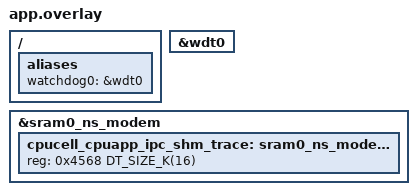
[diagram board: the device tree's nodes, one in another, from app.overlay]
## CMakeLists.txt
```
# SPDX-FileCopyrightText: 2026 ETH Zurich and University of Bologna
# SPDX-License-Identifier: Apache-2.0
#
# Authors:
# - Philip Wiese <wiesep@iis.ee.ethz.ch>

# SENSEI LPWAN shield firmware for the nRF9151 (NCS v3.4.1). It serves the nRF5340 over SPI.
# Board: sensei_lpwan_nrf9151/nrf9151/ns, from the SENSEI SDK.
#   export SENSEI_SDK_ROOT=<path to the SENSEI SDK>
#   cd $SENSEI_SDK_ROOT/NRF/apps/lpwan_shield
#   west build -b sensei_lpwan_nrf9151/nrf9151/ns -- -DEXTRA_ZEPHYR_MODULES=$SENSEI_SDK_ROOT/NRF \
#     -DEXTRA_CONF_FILE=conf/debug.conf

cmake_minimum_required(VERSION 3.20.0)

if(NOT DEFINED ENV{SENSEI_SDK_ROOT})
  message(FATAL_ERROR "Set SENSEI_SDK_ROOT to the SENSEI SDK.")
endif()

# The SDK provides the board, the devicetree bindings and the libraries sensei_link and sensei_lpwan.
list(APPEND EXTRA_ZEPHYR_MODULES $ENV{SENSEI_SDK_ROOT}/NRF)

find_package(Zephyr REQUIRED HINTS $ENV{ZEPHYR_BASE})
project(sensei_lpwan_shield)

target_sources(app PRIVATE
  src/main.c
  src/diag.c
  src/service.c
)
target_include_directories(app PRIVATE src)

if(CONFIG_LPWAN_SHIELD_SIM)
  # native_sim: the link is a socket, the modem and the LR1121 are fakes (sim/README.md). The headers of the modem
  # library, lte_lc and date_time are the real ones of NCS: the fakes must have their signatures.
  target_sources(app PRIVATE sim/sim_shield.c sim/sim_link.c)
  target_include_directories(app PRIVATE sim ${ZEPHYR_BASE}/boards/native/native_sim
    ${ZEPHYR_NRF_MODULE_DIR}/include ${ZEPHYR_NRFXLIB_MODULE_DIR}/nrf_modem/include)
  # what the Kconfig of the modem libraries would define on the board, and lte.c asks for
  target_compile_definitions(app PRIVATE
    CONFIG_LTE_LC_NETWORK_REGISTRATION_MODULE=1 CONFIG_LTE_LC_PSM_MODULE=1 CONFIG_LTE_LC_EDRX_MODULE=1
    CONFIG_LTE_LC_RAI_MODULE=1 CONFIG_LTE_LC_CONN_EVAL_MODULE=1 CONFIG_LTE_PROPRIETARY_PSM_REQ=1)
else()
  target_sources(app PRIVATE src/link.c)
endif()
# The trial rule and the image TLVs of the OTA helpers (pure headers, no Zephyr dependency): "ota/sensei_ota_trial.h",
# "ota/sensei_ota_image.h".
target_include_directories(app PRIVATE ${CMAKE_CURRENT_LIST_DIR}/../../system)

target_sources_ifdef(CONFIG_LPWAN_SHIELD_DFU app PRIVATE src/dfu.c)

if(CONFIG_LPWAN_SHIELD_DFU)
  # The kind of this board: sysbuild.cmake adds it to the signed image as a protected TLV (imgtool --custom-tlv 0xa0),
  # and the app takes the string from the same imgtool arguments, so the two cannot differ.
  if(CONFIG_MCUBOOT_EXTRA_IMGTOOL_ARGS MATCHES "--custom-tlv 0x[aA]0 ([^ ]+)")
    target_compile_definitions(app PRIVATE LPWAN_SHIELD_IMAGE_KIND="${CMAKE_MATCH_1}")
  else()
    message(FATAL_ERROR "The image kind TLV is missing in CONFIG_MCUBOOT_EXTRA_IMGTOOL_ARGS "
                        "('${CONFIG_MCUBOOT_EXTRA_IMGTOOL_ARGS}'): build with sysbuild (sysbuild.cmake sets it).")
  endif()
endif()

target_sources_ifdef(CONFIG_LPWAN_SHIELD_LTE app PRIVATE src/lte.c)
if(CONFIG_LPWAN_SHIELD_SIM AND CONFIG_LPWAN_SHIELD_LTE)
  target_sources(app PRIVATE sim/sim_modem.c)
endif()

target_sources_ifdef(CONFIG_LPWAN_SHIELD_GNSS app PRIVATE src/gnss.c)
if(CONFIG_LPWAN_SHIELD_SIM AND CONFIG_LPWAN_SHIELD_GNSS)
  target_sources(app PRIVATE sim/sim_gnss.c)
endif()

if(CONFIG_LPWAN_SHIELD_LORA)
  set(LR_DIR ${CMAKE_CURRENT_LIST_DIR}/third_party/lr1121_modem)
  target_sources(app PRIVATE src/lora.c)
  target_include_directories(app PRIVATE ${LR_DIR})
  if(CONFIG_LPWAN_SHIELD_SIM)
    # the driver calls that lora.c makes are faked (the headers are the driver's)
    target_sources(app PRIVATE sim/sim_lr1121.c)
  else()
    target_sources(app PRIVATE
      src/lr1121_zephyr_hal.c
      ${LR_DIR}/lr1121_modem_bsp.c
      ${LR_DIR}/lr1121_modem_driver_version.c
      ${LR_DIR}/lr1121_modem_lorawan.c
      ${LR_DIR}/lr1121_modem_lr_fhss.c
      ${LR_DIR}/lr1121_modem_modem.c
      ${LR_DIR}/lr1121_modem_radio_timings.c
      ${LR_DIR}/lr1121_modem_radio.c
      ${LR_DIR}/lr1121_modem_regmem.c
      ${LR_DIR}/lr1121_modem_relay.c
      ${LR_DIR}/lr1121_modem_system.c
    )
    # The Semtech driver is built as delivered; do not hold it to our warning level.
    set_source_files_properties(${LR_DIR}/lr1121_modem_lorawan.c ${LR_DIR}/lr1121_modem_radio.c
      PROPERTIES COMPILE_OPTIONS "-Wno-unused-parameter")
  endif()
endif()
```

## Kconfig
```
# SPDX-FileCopyrightText: 2026 ETH Zurich and University of Bologna
# SPDX-License-Identifier: Apache-2.0
#
# Authors:
# - Philip Wiese <wiesep@iis.ee.ethz.ch>

mainmenu "SENSEI LPWAN service (nRF9151)"

config LPWAN_SHIELD_SIM
	bool "Simulated shield on native_sim (link over a socket, fake LTE modem and LR1121)"
	depends on BOARD_NATIVE_SIM
	select SENSEI_LPWAN_SIM_HOST
	help
	  For tests without hardware: the SPI link is a TCP connection to the simulated node, the modem library, lte_lc and
	  the LR1121 driver are fakes (sim/), the LTE socket is a host socket. See sim/README.md.

config LPWAN_SHIELD_LTE
	bool "LTE-M and NB-IoT"
	default y
	select NETWORKING
	select NET_SOCKETS
	select NET_SOCKETS_OFFLOAD
	select NET_SOCKETS_POSIX_NAMES
	select NRF_MODEM_LIB if !LPWAN_SHIELD_SIM
	select LTE_LINK_CONTROL if !LPWAN_SHIELD_SIM
	select LTE_LC_PSM_MODULE if !LPWAN_SHIELD_SIM
	select LTE_LC_EDRX_MODULE if !LPWAN_SHIELD_SIM
	# modem sleep events: LpwanStatus.psm_entries counts the PSM entries
	select LTE_LC_MODEM_SLEEP_MODULE if !LPWAN_SHIELD_SIM
	select LTE_LC_MODEM_SLEEP_NOTIFICATIONS if !LPWAN_SHIELD_SIM
	select DATE_TIME if !LPWAN_SHIELD_SIM
	help
	  UDP or TCP uplink and downlink over the LTE modem. The modem library starts at the first
	  connect request.

# The modem reports a sleep only when it lasts this long: the shortest value, so that every PSM counts.
config LTE_LC_MODEM_SLEEP_NOTIFICATIONS_THRESHOLD_MS
	default 10240 if LPWAN_SHIELD_LTE

config LPWAN_SHIELD_LORA
	bool "LoRaWAN on the LR1121 (Modem-E firmware)"
	default y
	help
	  LoRaWAN class A (class C on request), OTAA, over the LR1121 on the shield.

if LPWAN_SHIELD_LTE

config LPWAN_SHIELD_LTE_STACK
	int "LTE worker stack size"
	default 4096

config LPWAN_SHIELD_LTE_CONNECT_TIMEOUT_S
	int "Time to wait for the network registration, s"
	default 600

config LPWAN_SHIELD_LTE_TIME_WAIT_S
	int "Time to wait for the network time after connect, s"
	default 10

config LPWAN_SHIELD_RAI
	bool "Release assistance indication (RAI) on the last chunk of an LTE message"
	default y
	select LTE_LC_RAI_MODULE if !LPWAN_SHIELD_SIM
	select LTE_RAI_REQ if !LPWAN_SHIELD_SIM
	help
	  The client marks the last chunk of a message (Send.rai); the shield sets the RAI socket option for that send
	  and, if the server is expected to answer, waits for the answer and then tells the modem that nothing more is
	  coming. The modem leaves the connected state at once and not after the network's inactivity timer. Whether the
	  network acts on it depends on the operator: see LpwanStatus.rai_support. Without it the option is never set.

config LPWAN_SHIELD_LTE_ANSWER_WAIT_S
	int "Time to wait for the answer of the server after the last chunk (one-response RAI), LTE-M, s"
	default 10
	range 1 35
	depends on LPWAN_SHIELD_RAI
	help
	  The collector answers every LTE uplink with one datagram (a downlink or a 3-byte ack). The time counts from
	  send(), so it includes the RRC set-up of the modem (about 3 s on LTE-M). Without an answer in this time the send
	  is reported as "sent, unconfirmed" (TxDone.unconfirmed, ok is true), not as a failure, and the modem is told
	  that nothing more is expected. The wait ends early when the coverage is lost.

config LPWAN_SHIELD_LTE_ANSWER_WAIT_NBIOT_S
	int "The same for NB-IoT, s"
	default 30
	range 1 35
	depends on LPWAN_SHIELD_RAI
	help
	  NB-IoT at coverage level 1 and 2 repeats every transmission, so a 1 kB uplink and its answer can take 10 to 30 s.
	  Both waits plus 10 s must stay below LPWAN_SHIELD_SEND_TIMEOUT_S.

config LPWAN_SHIELD_LTE_EVAL
	bool "Connection evaluation (%CONEVAL) on request of the client"
	default y
	select LTE_LC_CONN_EVAL_MODULE if !LPWAN_SHIELD_SIM
	help
	  The client asks before a send that can wait (lte_eval); the result (energy estimate, RSRP, coverage level) is an
	  event. The node defers non-urgent data when the estimate is bad.

config LPWAN_SHIELD_GNSS
	bool "GNSS of the nRF9151: one fix on request"
	default y
	select MODEM_ANTENNA if !LPWAN_SHIELD_SIM
	help
	  The nRF5340 asks for a fix (gnss_fix) and gets position, time and time to fix as an event. GNSS is in the system mode
	  of the modem (LTE-M or NB-IoT with GPS) and active (functional mode 31) only for an attempt; it also works with LTE
	  off. It runs only while LTE is idle (PSM, eDRX gaps, LTE off). The active antenna of the shield is supplied
	  through the modem's COEX0 pin (AT%XCOEX0, set by the NCS library modem_antenna). No A-GNSS. Needs the modem
	  library, so it comes with LPWAN_SHIELD_LTE. See README.md.
	depends on LPWAN_SHIELD_LTE

if LPWAN_SHIELD_GNSS

config LPWAN_SHIELD_GNSS_STACK
	int "GNSS worker stack size"
	default 2560

# COEX0 switches the supply of the GNSS antenna (EN_3V3_GNSS_ANT, load switch U5): high while GNSS is active in
# 1565 to 1586 MHz. This is the string of Nordic's modem_antenna library for an antenna with an LNA that COEX0 controls
# (what the library calls the "onboard" case). No MAGPIO: the shield has no antenna tuner on those pins.
config MODEM_ANTENNA_AT_COEX0
	default "AT\%XCOEX0=1,1,1565,1586"

endif # LPWAN_SHIELD_GNSS

config LPWAN_SHIELD_PROPRIETARY_PSM
	bool "Proprietary PSM when the network grants no PSM"
	default y
	select LTE_PROPRIETARY_PSM_REQ if !LPWAN_SHIELD_SIM
	help
	  The modem sleeps as in PSM although the network did not grant it (AT%FEACONF). It acts only when the
	  network grants no PSM. Needs a modem firmware that has it (mfw_nrf91x1); on others the request is ignored.

endif # LPWAN_SHIELD_LTE

if LPWAN_SHIELD_LORA

config LPWAN_SHIELD_LORA_STACK
	int "LoRa worker stack size"
	default 3072

config LPWAN_SHIELD_LORA_JOIN_ATTEMPTS
	int "Join attempts before giving up"
	default 10

config LPWAN_SHIELD_LORA_TX_OFFSET_DB
	int "TX power offset of the RF path, dB"
	default -2
	help
	  Compensation for the shield's RF switch and matching, found during commissioning.

endif # LPWAN_SHIELD_LORA

config LPWAN_SHIELD_SEND_TIMEOUT_S
	int "Time for a send to report its result before it is failed, s"
	default 45
	help
	  Without a tx_done the state machine would stay in SENDING and every later send would be refused.
	  Used when the backend has no estimate (LTE). A LoRa send is given the time the LR1121 needs (duty-cycle wait,
	  transmissions with their repeats, at most 10 min) plus 5 s, if that is longer. While the LR1121 still holds the
	  frame the send is not failed then; the LR1121 is reset after twice that time. The client waits 15 s more at the least
	  (SENSEI_LPWAN_TX_TIMEOUT_S, 60 s), so this side answers first.

config LPWAN_SHIELD_DFU
	bool "Update over the air: the app (MCUboot) and the modem firmware (delta)"
	default y
	depends on BOOTLOADER_MCUBOOT
	select FLASH
	select FLASH_MAP
	select STREAM_FLASH
	select IMG_MANAGER
	help
	  The nRF5340 sends the new image over the SPI link (lpwan.proto, dfu_* requests); the app writes it into the
	  second MCUboot slot, or hands a delta patch to the modem. The new app confirms itself after the handshake with the
	  nRF5340 (dfu_confirm). Needs MCUboot from sysbuild (sysbuild.conf). See README.md.

config LPWAN_SHIELD_MODEM_DFU
	bool "Modem firmware update (nrf_modem_delta_dfu)"
	default y
	depends on LPWAN_SHIELD_DFU && LPWAN_SHIELD_LTE

config LPWAN_SHIELD_MODEM_DFU_STACK
	int "Stack of the work queue that starts the modem library and runs the modem update"
	default 3072
	depends on LPWAN_SHIELD_MODEM_DFU

config LPWAN_SHIELD_DFU_HOLD_S
	int "Time an update sender may be quiet before the radios are free again, s"
	default 150
	range 30 3600
	depends on LPWAN_SHIELD_DFU
	help
	  While a transfer is open the radios stay idle (flash, CPU). If no update request came for this long the sender
	  is gone: the radios work again. The transfer stays and can be resumed. Longer than the 120 s after which the
	  nRF5340 ends its update session. A running modem update holds the radios whatever this says.

config LPWAN_SHIELD_CONFIRM_DELAY_S
	int "Run time before a new app image confirms itself, s"
	default 5
	range 1 600
	depends on LPWAN_SHIELD_DFU
	help
	  After an update the image runs on trial. It confirms itself when it has run this long and the nRF5340 has
	  accepted the handshake (dfu_confirm for this image, sent after the protocol, the update support and a status
	  request were checked, and sent again until the image has confirmed).

config LPWAN_SHIELD_TRIAL_TIMEOUT_S
	int "Trial time of a new app image, s"
	default 180
	range 30 3600
	depends on LPWAN_SHIELD_DFU
	help
	  If the image is still unconfirmed after this time (the nRF5340 did not accept it), the shield resets and MCUboot
	  goes back to the old image. Any reset or power cycle of an unconfirmed image does the same.

config LPWAN_SHIELD_LINK_STACK
	int "SPI link thread stack size"
	default 3072 if LPWAN_SHIELD_DFU
	default 2048
	help
	  The update runs on this thread (flash writes, the read-back hash): it needs the larger size.

config LPWAN_SHIELD_LINK_PRIO
	int "SPI link thread priority (preemptible, lower is higher)"
	default 2

config LPWAN_SHIELD_WORKER_PRIO
	int "Priority of the LTE and LoRa workers (lower is higher)"
	default 6

config LPWAN_SHIELD_LOG_LEVEL
	int "Log level of the service modules (0 off ... 4 debug)"
	default 3

# A modem fault resets the chip (main.c). The choice is only there with the modem library.
choice NRF_MODEM_LIB_ON_FAULT
	default NRF_MODEM_LIB_ON_FAULT_APPLICATION_SPECIFIC
endchoice

source "Kconfig.zephyr"
```

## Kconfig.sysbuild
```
# SPDX-FileCopyrightText: 2026 ETH Zurich and University of Bologna
# SPDX-License-Identifier: Apache-2.0
#
# Authors:
# - Philip Wiese <wiesep@iis.ee.ethz.ch>

# Sysbuild options of the LPWAN shield app. MCUboot is part of every build (sysbuild.conf, sysbuild/mcuboot.conf,
# sysbuild.cmake). The public development key in Debug, a private key from the environment in Release. The shield has
# its own Release key, never the key of the nRF5340 node: an image of the node is then not accepted by the shield,
# and the other way round.

config SENSEI_RELEASE
	bool "Release build: sign with the Release key"
	help
	  Debug images are signed with MCUboot's public development key: anyone can sign for it, use it in the lab
	  only. A Release build needs its own private key: set SENSEI_SHIELD_MCUBOOT_KEY (path of a PEM file, ECDSA P-256;
	  there is no fallback to SENSEI_MCUBOOT_KEY, the key of the nRF5340 node), or pass
	  -DSB_CONFIG_BOOT_SIGNATURE_KEY_FILE=<path>. The build stops if the file is missing. Use it together with
	  -DEXTRA_CONF_FILE=conf/release.conf.

# The Release key comes from the environment (an empty value stops the build, see sysbuild.cmake).
# Debug keeps MCUboot's default key.
config BOOT_SIGNATURE_KEY_FILE
	default "$(SENSEI_SHIELD_MCUBOOT_KEY)" if SENSEI_RELEASE

source "share/sysbuild/Kconfig"
```

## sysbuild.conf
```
# SPDX-FileCopyrightText: 2026 ETH Zurich and University of Bologna
# SPDX-License-Identifier: Apache-2.0
#
# Authors:
# - Philip Wiese <wiesep@iis.ee.ethz.ch>

# MCUboot is part of every build (Debug and Release); its own options are in sysbuild/mcuboot.conf. The signed image
# is TF-M and the shield app in one (merged) file. See README.md, section "Update over the air".
SB_CONFIG_BOOTLOADER_MCUBOOT=y
SB_CONFIG_BOOT_SIGNATURE_TYPE_ECDSA_P256=y
# Swap with revert, no scratch area: the new image is tested first and MCUboot goes back to the old one if it is not
# confirmed.
SB_CONFIG_MCUBOOT_MODE_SWAP_USING_MOVE=y
```

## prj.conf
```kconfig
# SPDX-FileCopyrightText: 2026 ETH Zurich and University of Bologna
# SPDX-License-Identifier: Apache-2.0
#
# Authors:
# - Philip Wiese <wiesep@iis.ee.ethz.ch>

# Link protocol of the SDK library sensei_lpwan (selects sensei_link: framing, nanopb glue, messages).
CONFIG_SENSEI_LPWAN_PROTO=y

CONFIG_GPIO=y
CONFIG_SPI=y
CONFIG_SPI_SLAVE=y
CONFIG_SPI_ASYNC=y
CONFIG_PM_DEVICE=y

# Memory
CONFIG_MAIN_STACK_SIZE=2048
CONFIG_SYSTEM_WORKQUEUE_STACK_SIZE=2048
CONFIG_HEAP_MEM_POOL_SIZE=4096

# Networking: the modem's offloaded socket API only
CONFIG_NET_NATIVE=n
CONFIG_NRF_MODEM_LIB_NET_IF=n
CONFIG_DATE_TIME_NTP=n

# Watchdog: task watchdog (the link thread) with the hardware watchdog as fallback; a modem fault resets the chip.
CONFIG_WATCHDOG=y
CONFIG_TASK_WDT=y
CONFIG_TASK_WDT_HW_FALLBACK=y
CONFIG_REBOOT=y

# Field diagnostics: reset cause, boot count and the last fatal error (also of the modem core) in retained RAM,
# reported to the nRF5340 in LpwanStatus. The fatal handler records the error and resets the chip.
CONFIG_SENSEI_DIAG=y

CONFIG_SIZE_OPTIMIZATIONS=y
```

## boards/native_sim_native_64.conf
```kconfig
# SPDX-FileCopyrightText: 2026 ETH Zurich and University of Bologna
# SPDX-License-Identifier: Apache-2.0
#
# Authors:
# - Philip Wiese <wiesep@iis.ee.ethz.ch>

# Simulated shield on native_sim (sim/README.md): the link to the nRF5340 is a socket, the LTE modem and the LR1121 are
# fakes, the LTE socket is a host socket (offloaded sockets).
CONFIG_LPWAN_SHIELD_SIM=y

# no SPI slave, watchdog or bootloader on the host
CONFIG_SPI=n
CONFIG_SPI_SLAVE=n
CONFIG_SPI_ASYNC=n
CONFIG_PM_DEVICE=n
CONFIG_WATCHDOG=n
CONFIG_TASK_WDT=n
CONFIG_TASK_WDT_HW_FALLBACK=n
CONFIG_LPWAN_SHIELD_DFU=n

# UDP to the collector through the host
CONFIG_GPIO_EMUL=y
CONFIG_NET_L2_ETHERNET=n
CONFIG_ETH_NATIVE_TAP=n
CONFIG_NET_DRIVERS=y
CONFIG_NET_NATIVE_OFFLOADED_SOCKETS=y
CONFIG_NET_IPV4=y
CONFIG_NET_IPV6=n

# a restart of the process is the reset of the shield (a lost power, a modem fault)
CONFIG_NATIVE_SIM_REBOOT=y

CONFIG_LOG=y
CONFIG_LOG_MODE_IMMEDIATE=y
CONFIG_LOG_BACKEND_SHOW_COLOR=n
CONFIG_ASSERT=y
CONFIG_HW_STACK_PROTECTION=n
CONFIG_MAIN_STACK_SIZE=4096
CONFIG_SYSTEM_WORKQUEUE_STACK_SIZE=4096
CONFIG_HEAP_MEM_POOL_SIZE=16384
CONFIG_SIZE_OPTIMIZATIONS=n
```

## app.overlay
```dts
/*
 * SPDX-FileCopyrightText: 2026 ETH Zurich and University of Bologna
 * SPDX-License-Identifier: Apache-2.0
 *
 * Authors:
 * - Philip Wiese <wiesep@iis.ee.ethz.ch>
 */

/* The task watchdog uses the hardware watchdog as fallback (main.c, link.c). */
/ {
	aliases {
		watchdog0 = &wdt0;
	};
};

&wdt0 {
	status = "okay";
};

/* Region for the modem trace (conf/debug.conf, CONFIG_NRF_MODEM_LIB_TRACE): 16 kB in the part of the modem's 40 kB
 * that nothing else uses (after the IPC regions, which end at 0x4568). Nothing uses it in the Release build. */
&sram0_ns_modem {
	cpucell_cpuapp_ipc_shm_trace: sram0_ns_modem@4568 {
		/* Modem trace */
		reg = <0x4568 DT_SIZE_K(16)>;
	};
};
```

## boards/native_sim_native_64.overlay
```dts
/*
 * SPDX-FileCopyrightText: 2026 ETH Zurich and University of Bologna
 * SPDX-License-Identifier: Apache-2.0
 *
 * Authors:
 * - Philip Wiese <wiesep@iis.ee.ethz.ch>
 */

/* Simulated shield (native_sim). Used instead of app.overlay, which is for the nRF9151. The event line of the LR1121
 * (DIO9) is an emulated GPIO pin that the fake radio drives (sim/sim_lr1121.c). The node borrows the binding of the
 * link lines, which also asks for a busy line (not used). */

#include <zephyr/dt-bindings/gpio/gpio.h>

/ {
	sim_lr1121: sim-lr1121 {
		compatible = "sensei,lpwan-link";
		busy-gpios = <&gpio0 6 GPIO_ACTIVE_HIGH>;
		event-gpios = <&gpio0 5 GPIO_ACTIVE_HIGH>;
	};
};
```

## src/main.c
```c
/*
 * SPDX-FileCopyrightText: 2026 ETH Zurich and University of Bologna
 * SPDX-License-Identifier: Apache-2.0
 *
 * Authors:
 * - Philip Wiese <wiesep@iis.ee.ethz.ch>
 */

/**
 * @file main.c
 * @brief nRF9151 LPWAN service: SPI slave to the nRF5340, LTE-M/NB-IoT and LoRaWAN (LR1121).
 */

#include <zephyr/device.h>
#include <zephyr/kernel.h>
#include <zephyr/logging/log.h>
#include <zephyr/sys/reboot.h>
#include <zephyr/task_wdt/task_wdt.h>

#ifdef CONFIG_LPWAN_SHIELD_LTE
#include <modem/nrf_modem_lib.h>
#endif

#include "dfu.h"
#include "diag.h"
#ifdef CONFIG_LPWAN_SHIELD_GNSS
#include "gnss.h"
#endif
#include "lora.h"
#include "lte.h"

LOG_MODULE_REGISTER(main, CONFIG_LPWAN_SHIELD_LOG_LEVEL);

int service_start(void);

#ifdef CONFIG_LPWAN_SHIELD_SIM
#include "sim_shield.h"
#endif

#ifdef CONFIG_LPWAN_SHIELD_LTE
/*
 * The modem core crashed. The default handler only logs, and the LTE backend would then wait for ever
 * for a modem that is gone. Reset the whole chip: the nRF5340 sees the link drop, power-cycles the shield
 * if it does not come back, and connects again (CONFIG_NRF_MODEM_LIB_ON_FAULT_APPLICATION_SPECIFIC).
 */
void nrf_modem_fault_handler(struct nrf_modem_fault_info *fault) {
  LOG_ERR("modem fault 0x%x at 0x%x: reset", (unsigned)fault->reason, (unsigned)fault->program_counter);
  diag_modem_fault(fault->reason, fault->program_counter); /* reported to the nRF5340 after the reset */
  sys_reboot(SYS_REBOOT_COLD);
}
#endif

int main(void) {
  int err;

#ifdef CONFIG_LPWAN_SHIELD_SIM
  sim_shield_start(); /* no watchdog on native_sim */
#else
  /* Task watchdog with the hardware watchdog behind it: the link thread feeds it (link.c). A frozen kernel or a
   * link thread that cannot re-arm the SPI slave resets the chip. */
  err = task_wdt_init(DEVICE_DT_GET(DT_ALIAS(watchdog0)));
  if (err) {
    LOG_ERR("watchdog init failed: %d", err);
  }
#endif
  diag_init();
  /* The update state and the trial supervision are ready before the first request. */
  dfu_init();
  /* The link comes first so the master gets answers while the radios start. */
  err = service_start();
  if (err) {
    LOG_ERR("link start failed: %d", err);
    return err;
  }
#ifdef CONFIG_LPWAN_SHIELD_LTE
  err = lte_init();
  if (err) {
    LOG_ERR("LTE init failed: %d", err);
  }
#endif
#ifdef CONFIG_LPWAN_SHIELD_GNSS
  err = gnss_init();
  if (err) {
    LOG_ERR("GNSS init failed: %d", err);
  }
#endif
#ifdef CONFIG_LPWAN_SHIELD_LORA
  err = lora_init();
  if (err) {
    LOG_ERR("LoRa init failed: %d", err);
  }
#endif
  LOG_INF("nRF9151 LPWAN service up");
  /* Everything else runs in threads: the main thread has nothing to do. */
  return 0;
}
```

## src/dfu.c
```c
/*
 * SPDX-FileCopyrightText: 2026 ETH Zurich and University of Bologna
 * SPDX-License-Identifier: Apache-2.0
 *
 * Authors:
 * - Philip Wiese <wiesep@iis.ee.ethz.ch>
 *
 */

/*
 * App target: the signed image (TF-M and app, one MCUboot image) is written into slot 1 of the flash map
 * (`slot1_partition`, 448 kB at 0x80000). The checkpoints of the transfer are in the first sector of the
 * `storage_partition` (TF-M NS storage is on: the sector is non-secure). The image must carry the kind TLV of this
 * board (checked at `finish`). `dfu_apply` erases the trailer of slot 1 and marks it for one trial boot; `dfu_abort`
 * erases the trailer again. The nRF5340 then cuts the shield power and powers it again, MCUboot swaps and starts the
 * new image, which runs on trial until the nRF5340 accepts the handshake (dfu_confirm, for this image id). Any reset
 * before that brings the old image back.
 *
 * Modem target: nrf_modem_delta_dfu. The delta patch goes to the modem in the order it arrives; the modem erases its
 * DFU area first (minutes), then takes the patch and checks its signature itself. The update runs in the modem at the
 * next start of the modem library. The library is started and restarted on a work queue of its own, so the link
 * thread keeps answering (and feeding its watchdog); the status says ERASING until the modem is ready.
 */

#include <errno.h>
#include <string.h>

#include <zephyr/dfu/mcuboot.h>
#include <zephyr/kernel.h>
#include <zephyr/logging/log.h>
#include <zephyr/storage/flash_map.h>
#include <zephyr/sys/atomic.h>
#include <zephyr/sys/byteorder.h>
#include <zephyr/sys/reboot.h>

#ifdef CONFIG_LPWAN_SHIELD_MODEM_DFU
#include <modem/nrf_modem_lib.h>
#include <nrf_errno.h>
#include <nrf_modem.h>
#include <nrf_modem_delta_dfu.h>
#endif

#include "dfu.h"
#include "diag/sensei_diag_rt.h"
#include "link.h"
#include "lte.h"
#include "ota/sensei_ota_image.h"
#include "ota/sensei_ota_trial.h"
#include "sensei_lpwan/lpwan_dfu.h"

LOG_MODULE_REGISTER(dfu, CONFIG_LPWAN_SHIELD_LOG_LEVEL);

#define SLOT0_ID PARTITION_ID(slot0_partition)
#define SLOT1_ID PARTITION_ID(slot1_partition)
#define STORE_ID PARTITION_ID(storage_partition)

/* The delta patches are far below this; at the start the modem refuses a patch that does not fit its DFU area. */
#define MODEM_PATCH_MAX (2u * 1024u * 1024u)

static struct lpwan_dfu core;
static const struct flash_area *slot1;
static const struct flash_area *store;

/* ---- app: slot 1 and the checkpoint sector ---- */

static int open_areas(void) {
  int err;

  if (slot1 == NULL) {
    err = flash_area_open(SLOT1_ID, &slot1);
    if (err) {
      slot1 = NULL;
      return err;
    }
  }
  if (store == NULL) {
    err = flash_area_open(STORE_ID, &store);
    if (err) {
      store = NULL; /* no checkpoints: the transfer runs, a restart of the shield starts it again at 0 */
    }
  }
  return 0;
}

/* The end of slot 1 holds the MCUboot trailer (magic, flags, swap status: about 1.6 kB for 128 sectors), and the
 * swap with move needs one free sector. The image gets what is left. */
#define TRAILER_SECTORS 2u
#define SPARE_SECTORS 1u

static uint32_t app_capacity(void *ctx, sensei_DfuTarget t) {
  ARG_UNUSED(ctx);
  ARG_UNUSED(t);
  return open_areas() == 0 ? (uint32_t)slot1->fa_size - (TRAILER_SECTORS + SPARE_SECTORS) * LPWAN_DFU_SECTOR : 0;
}

/* Erase the trailer of slot 1: stale bytes of an earlier swap make the marking fail, and without it the marking is
 * gone. */
static int erase_trailer(void) {
  for (unsigned i = TRAILER_SECTORS; i > 0; i--) {
    int err = flash_area_erase(slot1, slot1->fa_size - i * LPWAN_DFU_SECTOR, LPWAN_DFU_SECTOR);

    if (err) {
      return err;
    }
    link_feed_watchdog();
  }
  return 0;
}

static int app_open(void *ctx, sensei_DfuTarget t, uint32_t size, bool fresh) {
  ARG_UNUSED(ctx);
  ARG_UNUSED(t);
  ARG_UNUSED(size);
  ARG_UNUSED(fresh);
  return open_areas();
}

static int app_erase(void *ctx, uint32_t off, uint32_t len) {
  ARG_UNUSED(ctx);
  return flash_area_erase(slot1, off, len);
}

static int app_write(void *ctx, uint32_t off, const uint8_t *data, size_t len) {
  ARG_UNUSED(ctx);
  return flash_area_write(slot1, off, data, len);
}

static int app_read(void *ctx, uint32_t off, uint8_t *data, size_t len) {
  ARG_UNUSED(ctx);
  return flash_area_read(slot1, off, data, len);
}

static int log_read(void *ctx, uint32_t off, uint8_t *data, size_t len) {
  ARG_UNUSED(ctx);
  return store != NULL ? flash_area_read(store, off, data, len) : -ENODEV;
}

static int log_write(void *ctx, uint32_t off, const uint8_t *data, size_t len) {
  ARG_UNUSED(ctx);
  return store != NULL ? flash_area_write(store, off, data, len) : -ENODEV;
}

static int log_erase(void *ctx) {
  ARG_UNUSED(ctx);
  return store != NULL ? flash_area_erase(store, 0, LPWAN_DFU_SECTOR) : -ENODEV;
}

static int app_headers(void *ctx, uint8_t new_hdr[32], uint8_t running_hdr[32]) {
  const struct flash_area *s0;
  int err;

  ARG_UNUSED(ctx);
  err = flash_area_read(slot1, 0, new_hdr, 32);
  if (err) {
    return err;
  }
  err = flash_area_open(SLOT0_ID, &s0);
  if (err) {
    return err;
  }
  err = flash_area_read(s0, 0, running_hdr, 32);
  flash_area_close(s0);
  return err;
}

static int app_apply(void *ctx, sensei_DfuTarget t) {
  int err;

  ARG_UNUSED(ctx);
  ARG_UNUSED(t);
  err = erase_trailer();
  if (err) {
    return err;
  }
  /* One test boot: MCUboot swaps, and goes back at the next reset unless the new image confirms itself. */
  return boot_request_upgrade(BOOT_UPGRADE_TEST);
}

static int app_unmark(void *ctx) {
  ARG_UNUSED(ctx);
  return erase_trailer(); /* no marking, no swap at the next power-up */
}

static int slot1_read(void *ctx, uint32_t off, void *buf, size_t len) {
  ARG_UNUSED(ctx);
  return flash_area_read(slot1, off, buf, len);
}

/* The kind TLV is protected: the signature covers it, so it is the board the image was built and signed for. */
static sensei_DfuFail app_kind(void *ctx) {
  ARG_UNUSED(ctx);
  if (sensei_image_kind_is(slot1_read, NULL, LPWAN_SHIELD_IMAGE_KIND)) {
    return sensei_DfuFail_DFU_FAIL_NONE;
  }
  LOG_ERR("the image is not for this board (no kind TLV '%s')", LPWAN_SHIELD_IMAGE_KIND);
  return sensei_DfuFail_DFU_FAIL_BOARD;
}

static void kick(void *ctx) {
  ARG_UNUSED(ctx);
  link_feed_watchdog();
}

static const struct lpwan_dfu_ops app_ops = {
    .capacity = app_capacity,
    .open = app_open,
    .erase = app_erase,
    .write = app_write,
    .read = app_read,
    .log_read = log_read,
    .log_write = log_write,
    .log_erase = log_erase,
    .read_headers = app_headers,
    .apply = app_apply,
    .unmark = app_unmark,
    .check_kind = app_kind,
    .kick = kick,
};

/* ---- modem ---- */

#ifdef CONFIG_LPWAN_SHIELD_MODEM_DFU

/* The modem library is started, and restarted for the update, on a work queue of its own: nrf_modem_lib_init() takes
 * seconds, and minutes while the modem installs an update. The link thread must go on answering. */
static K_THREAD_STACK_DEFINE(modem_wq_stack, CONFIG_LPWAN_SHIELD_MODEM_DFU_STACK);
static struct k_work_q modem_wq;

static bool erase_pending;
static bool write_open;
static struct nrf_modem_delta_dfu_uuid uuid_before;
static bool uuid_known;

enum { OPEN_NONE = 0, OPEN_RUNNING, OPEN_OK, OPEN_FAILED };
static atomic_t open_job;
static int open_err; /* OPEN_FAILED: negative errno, or the modem's positive error code */
static uint32_t open_size;
static bool open_fresh;
static struct k_work open_work;

static atomic_t apply_result; /* 0 running, 1 done, negative: failed (detail in apply_detail) */
static int apply_detail;
static struct k_work apply_work;

/* On modem_wq: start the library, check that the patch fits, and erase the DFU area if needed. */
static int modem_open_sync(uint32_t size, bool fresh) {
  struct nrf_modem_delta_dfu_uuid uuid;
  size_t area = 0, off = 0;
  int err;

  err = lte_modem_init();
  if (err) {
    return err;
  }
  err = nrf_modem_delta_dfu_uuid(&uuid);
  uuid_known = err == 0;
  if (uuid_known) {
    uuid_before = uuid;
    LOG_INF("modem firmware %.*s", (int)sizeof(uuid.data), uuid.data);
  }
  err = nrf_modem_delta_dfu_area(&area);
  if (err) {
    return err > 0 ? err : -EIO;
  }
  if (size > area) {
    LOG_ERR("patch of %u B does not fit the modem DFU area (%u B)", (unsigned)size, (unsigned)area);
    return -EFBIG;
  }
  err = nrf_modem_delta_dfu_offset(&off);
  if (err != 0 && err != NRF_MODEM_DELTA_DFU_ERASE_PENDING) {
    return err > 0 ? err : -EIO;
  }
  erase_pending = err == NRF_MODEM_DELTA_DFU_ERASE_PENDING;
  if (fresh && !erase_pending && off != 0) { /* data of an earlier transfer, or a dirty area: erase it */
    err = nrf_modem_delta_dfu_erase();
    if (err != 0 && err != NRF_MODEM_DELTA_DFU_ERASE_PENDING) {
      return err > 0 ? err : -EIO;
    }
    erase_pending = true;
  }
  return 0;
}

static void open_fn(struct k_work *w) {
  ARG_UNUSED(w);
  open_err = modem_open_sync(open_size, open_fresh);
  atomic_set(&open_job, open_err ? OPEN_FAILED : OPEN_OK);
}

static int modem_finish(void) {
  int err = 0;

  if (write_open) {
    err = nrf_modem_delta_dfu_write_done();
    write_open = false;
  }
  return err == 0 ? 0 : (err > 0 ? err : -EIO);
}

/* Returns at once: the work runs on modem_wq and modem_busy() says when it is done. */
static int modem_open(uint32_t size, bool fresh) {
  if (atomic_get(&open_job) == OPEN_RUNNING) {
    return 0;
  }
  (void)modem_finish(); /* the write session of an earlier transfer that failed is closed */
  open_size = size;
  open_fresh = fresh;
  erase_pending = false;
  atomic_set(&open_job, OPEN_RUNNING);
  k_work_submit_to_queue(&modem_wq, &open_work);
  return 0;
}

/* > 0 while the modem library starts or the modem erases its DFU area (it can take minutes), 0 ready, < 0 an error. */
static int modem_busy(void) {
  size_t off;
  int err;

  switch (atomic_get(&open_job)) {
  case OPEN_RUNNING:
    return 1;
  case OPEN_FAILED:
    return open_err == 0 ? -EIO : (open_err > 0 ? -open_err : open_err);
  default:
    break;
  }
  if (!erase_pending) {
    return 0;
  }
  err = nrf_modem_delta_dfu_offset(&off);
  if (err == 0) {
    erase_pending = false;
    return 0;
  }
  if (err == NRF_MODEM_DELTA_DFU_ERASE_PENDING || err == NRF_MODEM_DELTA_DFU_INVALID_DATA) {
    return 1;
  }
  return err > 0 ? -err : err;
}

static int modem_write(const uint8_t *data, size_t len) {
  int err;

  if (!write_open) {
    err = nrf_modem_delta_dfu_write_init();
    if (err != 0 && err != -NRF_EALREADY) {
      return err > 0 ? err : -EIO;
    }
    write_open = true;
  }
  err = nrf_modem_delta_dfu_write(data, len);
  return err; /* 0, a negative library error or a positive modem error: the core reports it in `detail` */
}

static int dfu_result;
NRF_MODEM_LIB_ON_DFU_RES(sensei_dfu, on_dfu_res, NULL);
static void on_dfu_res(int dfu_res, void *ctx) {
  ARG_UNUSED(ctx);
  dfu_result = dfu_res;
}

/* On modem_wq: the update runs when the modem library starts, so shut it down and start it again. Success is the
 * result the library reports (NRF_MODEM_DFU_RESULT_OK), or, when it reports nothing, a modem UUID that changed. A
 * result of VOLTAGE_LOW is a failure here; the modem tries again at its next start (the next LTE connect). */
static void apply_fn(struct k_work *w) {
  struct nrf_modem_delta_dfu_uuid now;
  bool ok = false;
  int err;

  ARG_UNUSED(w);
  dfu_result = 0;
  err = nrf_modem_lib_shutdown();
  if (err == 0) {
    err = nrf_modem_lib_init();
  }
  lte_modem_restarted(err == 0);
  if (err == 0) {
    if (dfu_result == (int)NRF_MODEM_DFU_RESULT_OK) {
      ok = true;
    } else if (dfu_result == 0) {
      ok = uuid_known && nrf_modem_delta_dfu_uuid(&now) == 0 && memcmp(&now, &uuid_before, sizeof(now)) != 0;
    }
  }
  if (ok) {
    apply_detail = 0;
    atomic_set(&apply_result, 1);
    LOG_INF("modem firmware updated");
  } else {
    apply_detail = dfu_result != 0 ? dfu_result : (err != 0 ? err : -ENOMSG);
    atomic_set(&apply_result, -1);
    LOG_ERR("modem update failed: init %d, result 0x%x", err, (unsigned)dfu_result);
  }
}

static int modem_apply(void) {
  int err = nrf_modem_delta_dfu_update();

  if (err != 0) {
    return err > 0 ? err : -EIO;
  }
  atomic_set(&apply_result, 0);
  k_work_submit_to_queue(&modem_wq, &apply_work);
  return 0;
}

static int modem_apply_state(int *detail) {
  int r = (int)atomic_get(&apply_result);

  *detail = apply_detail;
  return r;
}

static uint32_t modem_capacity(void *ctx, sensei_DfuTarget t) {
  ARG_UNUSED(ctx);
  ARG_UNUSED(t);
  return MODEM_PATCH_MAX;
}

static int modem_op_open(void *ctx, sensei_DfuTarget t, uint32_t size, bool fresh) {
  ARG_UNUSED(ctx);
  ARG_UNUSED(t);
  return modem_open(size, fresh);
}

static int modem_op_busy(void *ctx) {
  ARG_UNUSED(ctx);
  return modem_busy();
}

static int modem_op_write(void *ctx, uint32_t off, const uint8_t *data, size_t len) {
  ARG_UNUSED(ctx);
  ARG_UNUSED(off); /* the modem takes the patch in order */
  return modem_write(data, len);
}

static int modem_op_finish(void *ctx, sensei_DfuTarget t) {
  ARG_UNUSED(ctx);
  ARG_UNUSED(t);
  return modem_finish();
}

static int modem_op_apply(void *ctx, sensei_DfuTarget t) {
  ARG_UNUSED(ctx);
  ARG_UNUSED(t);
  return modem_apply();
}

static int modem_op_state(void *ctx, int *detail) {
  ARG_UNUSED(ctx);
  return modem_apply_state(detail);
}

static const struct lpwan_dfu_ops modem_ops = {
    .capacity = modem_capacity,
    .open = modem_op_open,
    .busy = modem_op_busy,
    .write = modem_op_write,
    .finish = modem_op_finish,
    .apply = modem_op_apply,
    .apply_state = modem_op_state,
    .kick = kick,
};

#endif /* CONFIG_LPWAN_SHIELD_MODEM_DFU */

/* ---- image id and trial boot ---- */

static int slot0_read(void *ctx, uint32_t off, void *buf, size_t len) {
  return flash_area_read((const struct flash_area *)ctx, off, buf, len);
}

/* First 4 bytes of the SHA-256 TLV of the running image (the id the nRF5340 and the host see in LpwanVersion). */
static uint32_t running_image_id(void) {
  static uint32_t id;
  static bool known;
  const struct flash_area *fa;

  if (!known) {
    if (flash_area_open(SLOT0_ID, &fa) != 0) {
      return 0;
    }
    id = sensei_image_id(slot0_read, (void *)fa);
    flash_area_close(fa);
    known = true;
  }
  return id;
}

static atomic_t handshake_ok; /* the nRF5340 accepted this image (dfu_confirm for this image id) */
static struct k_work_delayable trial_work;

/* Called by the check every few seconds while the image is on trial. */
static void trial_fn(struct k_work *work) {
  struct sensei_ota_trial_in in = {
      .up_s = (uint32_t)(k_uptime_get() / 1000),
      .confirm_enabled = true,
      .confirm_delay_s = CONFIG_LPWAN_SHIELD_CONFIRM_DELAY_S,
      .timeout_s = CONFIG_LPWAN_SHIELD_TRIAL_TIMEOUT_S,
      .need_link = true,
      .link_seen = atomic_get(&handshake_ok) != 0,
      .healthy = true, /* the link thread answers: the nRF5340's request got here */
  };

  ARG_UNUSED(work);
  if (boot_is_img_confirmed()) {
    return;
  }
  switch (sensei_ota_trial_step(&in)) {
  case SENSEI_OTA_TRIAL_CONFIRM:
    if (boot_write_img_confirmed() == 0) {
      LOG_INF("image confirmed");
      return;
    }
    LOG_ERR("confirm failed");
    break;
  case SENSEI_OTA_TRIAL_REVERT:
    LOG_ERR("image not confirmed after %d s: reset, MCUboot goes back to the old image",
            CONFIG_LPWAN_SHIELD_TRIAL_TIMEOUT_S);
    k_msleep(100);
    sys_reboot(SYS_REBOOT_COLD);
    break;
  case SENSEI_OTA_TRIAL_WAIT:
    break;
  }
  k_work_reschedule(&trial_work, K_SECONDS(5));
}

void dfu_init(void) {
  sensei_diag_set_image_id(running_image_id()); /* a fault record names the image that faulted */
#ifdef CONFIG_LPWAN_SHIELD_MODEM_DFU
  k_work_queue_init(&modem_wq);
  k_work_queue_start(&modem_wq, modem_wq_stack, K_THREAD_STACK_SIZEOF(modem_wq_stack),
                     K_PRIO_PREEMPT(CONFIG_LPWAN_SHIELD_LINK_PRIO + 2), NULL);
  k_thread_name_set(&modem_wq.thread, "modem_dfu");
  k_work_init(&open_work, open_fn);
  k_work_init(&apply_work, apply_fn);
  lpwan_dfu_init(&core, &app_ops, &modem_ops, NULL);
#else
  lpwan_dfu_init(&core, &app_ops, NULL, NULL);
#endif
  if (boot_is_img_confirmed()) {
    return;
  }
  LOG_WRN("image is on trial: the nRF5340 must accept it within %d s or it reverts",
          CONFIG_LPWAN_SHIELD_TRIAL_TIMEOUT_S);
  k_work_init_delayable(&trial_work, trial_fn);
  k_work_schedule(&trial_work, K_SECONDS(5));
}

/* ---- requests ---- */

/* The radios wait while a transfer is open and its sender is around, and while the modem works. A sender that has
 * been quiet for CONFIG_LPWAN_SHIELD_DFU_HOLD_S lets the radios go (the transfer stays and can be resumed). */
bool dfu_holds_link(void) {
  return lpwan_dfu_holds_link(&core, k_uptime_get_32(), CONFIG_LPWAN_SHIELD_DFU_HOLD_S * 1000U);
}

void dfu_fill_version(sensei_LpwanVersion *v) {
  v->image_id = running_image_id();
  v->trial = !boot_is_img_confirmed();
  v->dfu_targets = lpwan_dfu_targets(&core);
}

sensei_LpwanResult dfu_handle(const sensei_LpwanRequest *req, sensei_LpwanResponse *rsp) {
  sensei_DfuStatus *st = &rsp->dfu;
  sensei_LpwanResult r;

  rsp->which_payload = sensei_LpwanResponse_dfu_tag;
  lpwan_dfu_touch(&core, k_uptime_get_32());
  switch (req->which_body) {
  case sensei_LpwanRequest_dfu_begin_tag:
    r = lpwan_dfu_begin(&core, &req->dfu_begin, st);
    LOG_INF("dfu begin: target %d, %u B, resume %d -> %d, offset %u", (int)req->dfu_begin.target,
            (unsigned)req->dfu_begin.size, (int)req->dfu_begin.resume, (int)r, (unsigned)st->offset);
    break;
  case sensei_LpwanRequest_dfu_chunk_tag:
    r = lpwan_dfu_chunk(&core, &req->dfu_chunk, st);
    break;
  case sensei_LpwanRequest_dfu_finish_tag:
    r = lpwan_dfu_finish(&core, st);
    LOG_INF("dfu finish -> %d, state %d, fail %d", (int)r, (int)st->state, (int)st->fail);
    break;
  case sensei_LpwanRequest_dfu_apply_tag:
    r = lpwan_dfu_apply(&core, st);
    LOG_INF("dfu apply -> %d, state %d, fail %d", (int)r, (int)st->state, (int)st->fail);
    break;
  case sensei_LpwanRequest_dfu_abort_tag:
    r = lpwan_dfu_abort(&core, st);
    LOG_INF("dfu abort -> %d, state %d", (int)r, (int)st->state);
    break;
  case sensei_LpwanRequest_dfu_confirm_tag:
    r = lpwan_dfu_status(&core, st);
    if (lpwan_dfu_confirm_allowed(req->dfu_confirm.image_id, running_image_id())) {
      atomic_set(&handshake_ok, 1); /* sent again until the image has confirmed: harmless to repeat */
    } else {
      LOG_WRN("dfu_confirm for image %08x, running %08x: ignored", (unsigned)req->dfu_confirm.image_id,
              (unsigned)running_image_id());
      st->fail = sensei_DfuFail_DFU_FAIL_STATE;
      r = sensei_LpwanResult_LPWAN_INVALID;
    }
    break;
  default:
    r = lpwan_dfu_status(&core, st);
    break;
  }
  return r;
}
```

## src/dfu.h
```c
/*
 * SPDX-FileCopyrightText: 2026 ETH Zurich and University of Bologna
 * SPDX-License-Identifier: Apache-2.0
 *
 * Authors:
 * - Philip Wiese <wiesep@iis.ee.ethz.ch>
 */

/**
 * @file dfu.h
 * @brief Update of the shield over the SPI link: the app goes into the second MCUboot slot, the modem firmware goes to
 *        the modem as a delta patch. The rules are in lib/sensei_lpwan (lpwan_dfu.h); this file is the flash, the
 *        modem and the trial boot behind them.
 */

#ifndef SENSEI_NRF9151_DFU_H_
#define SENSEI_NRF9151_DFU_H_

#include <stdbool.h>

#include "sensei_lpwan/lpwan_link.h"

#ifdef CONFIG_LPWAN_SHIELD_DFU

/** Start the trial supervision if the running image was just installed (call at the end of start-up). */
void dfu_init(void);

/** Handle a dfu_* request on the link thread. Fills rsp (payload dfu) and returns the result. */
sensei_LpwanResult dfu_handle(const sensei_LpwanRequest *req, sensei_LpwanResponse *rsp);

/** True while a transfer is open or an update runs: radios must stay idle. */
bool dfu_holds_link(void);

/** image_id, trial and dfu_targets of LpwanVersion. */
void dfu_fill_version(sensei_LpwanVersion *v);

#else

static inline void dfu_init(void) {}
static inline bool dfu_holds_link(void) { return false; }
static inline void dfu_fill_version(sensei_LpwanVersion *v) { (void)v; }

#endif

#endif /* SENSEI_NRF9151_DFU_H_ */
```

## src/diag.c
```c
/*
 * SPDX-FileCopyrightText: 2026 ETH Zurich and University of Bologna
 * SPDX-License-Identifier: Apache-2.0
 *
 * Authors:
 * - Philip Wiese <wiesep@iis.ee.ethz.ch>
 */

#include <string.h>

#include <zephyr/logging/log.h>

#include "diag.h"
#include "diag/sensei_diag_rt.h"

LOG_MODULE_DECLARE(main, CONFIG_LPWAN_SHIELD_LOG_LEVEL);

static struct sensei_diag_fault fault;
static volatile bool have_fault; /* until the node acks it (diag_ack): a lost status answer loses nothing */

void diag_init(void) {
  have_fault = sensei_diag_take_fault(&fault);
  if (have_fault) {
    LOG_WRN("last run ended with a fatal error: %s, pc 0x%08x, thread %s", sensei_diag_fault_reason_name(fault.reason),
            (unsigned)fault.pc, fault.thread);
  }
}

void diag_modem_fault(uint32_t reason, uint32_t pc) {
  sensei_diag_capture_ext(SENSEI_FAULT_MODEM, pc, 0, reason, "modem");
}

void diag_ack(void) {
  if (have_fault) {
    LOG_INF("fault record taken over by the node");
  }
  have_fault = false;
}

void diag_fill_status(sensei_LpwanStatus *st) {
  st->reset_cause = sensei_diag_reset_cause();
  st->boot_count = sensei_diag_boot_count();
  if (have_fault) {
    st->has_fault = true; /* every status, until diag_ack() */
    st->fault.reason = fault.reason;
    st->fault.pc = fault.pc;
    st->fault.lr = fault.lr;
    strncpy(st->fault.thread, fault.thread, sizeof(st->fault.thread) - 1);
    st->fault.uptime_s = fault.uptime_s;
    st->fault.last_job = fault.last_job;
    st->fault.image_id = fault.image_id;
    st->fault.boot_count = fault.boot_count;
    st->fault.status = fault.status;
    st->fault.coredump = (fault.flags & SENSEI_FAULT_FLAG_COREDUMP) != 0;
  }
}
```

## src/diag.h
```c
/*
 * SPDX-FileCopyrightText: 2026 ETH Zurich and University of Bologna
 * SPDX-License-Identifier: Apache-2.0
 *
 * Authors:
 * - Philip Wiese <wiesep@iis.ee.ethz.ch>
 */

/**
 * @file diag.h
 * @brief Diagnostics of the shield: reset cause, boot count and the last fatal error (SDK NRF/system/diag) for
 * the nRF5340, which asks with get_status.
 */

#ifndef LPWAN_SHIELD_DIAG_H_
#define LPWAN_SHIELD_DIAG_H_

#include "sensei/lpwan.pb.h"

/** Take over the record of the previous run. Call once at start. */
void diag_init(void);

/** A fault of the modem core: keep it in the fault record (it survives the reset that follows). */
void diag_modem_fault(uint32_t reason, uint32_t pc);

/** Reset cause, boot count and the last fault into a LpwanStatus. The fault is in every status until the node acks it
 *  (diag_ack). It is kept in RAM only: a reset or a power cut of the shield loses it. */
void diag_fill_status(sensei_LpwanStatus *st);

/** The node has stored the fault of the last status (request diag_ack): forget it. */
void diag_ack(void);

#endif /* LPWAN_SHIELD_DIAG_H_ */
```

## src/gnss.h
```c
/*
 * SPDX-FileCopyrightText: 2026 ETH Zurich and University of Bologna
 * SPDX-License-Identifier: Apache-2.0
 *
 * Authors:
 * - Philip Wiese <wiesep@iis.ee.ethz.ch>
 */

/**
 * @file gnss.h
 * @brief GNSS of the nRF9151: one fix on request (nrf_modem_gnss). The result is the gnss_result event.
 *
 * The rules (an LTE send goes through during a fix; LTE connect, release, configure, deep sleep and the shield update
 * and the fix exclude each other) are in sensei_lpwan/lpwan_gnss.h. No A-GNSS: the receiver starts from what the modem
 * keeps in its own memory. A power cycle of the shield between fixes is a warm start; a cold start needs
 * nrf_modem_gnss_nv_data_delete() (debug only, no command for it).
 */

#ifndef SENSEI_NRF9151_GNSS_H_
#define SENSEI_NRF9151_GNSS_H_

#include <stdbool.h>
#include <stdint.h>

#include "sensei_lpwan/lpwan_link.h"

int gnss_init(void);

/** Start a fix. seq is the request's, the result event carries it. timeout_s: 0 is the default, at most 900.
 *  Returns at once: OK, BUSY (a fix runs), INVALID (bad timeout). The checks against the state of the radios and the
 *  update are made by the caller (service.c, lpwan_admit_request). */
sensei_LpwanResult gnss_start(uint32_t seq, uint32_t timeout_s);

/** End the fix that runs, if any: the result event follows with status CANCELLED. */
sensei_LpwanResult gnss_cancel(void);

/** True from the start of a fix until its result event is queued. */
bool gnss_active(void);

/** Fill LpwanStatus gnss_attempts, gnss_fixes and gnss_on_ms. */
void gnss_fill_status(sensei_LpwanStatus *st);

#endif /* SENSEI_NRF9151_GNSS_H_ */
```

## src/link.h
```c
/*
 * SPDX-FileCopyrightText: 2026 ETH Zurich and University of Bologna
 * SPDX-License-Identifier: Apache-2.0
 *
 * Authors:
 * - Philip Wiese <wiesep@iis.ee.ethz.ch>
 */

/**
 * @file link.h
 * @brief SPI slave transport to the nRF5340: SPIS, BUSY/EVENT/ACK lines and the link thread.
 */

#ifndef SENSEI_NRF9151_LINK_H_
#define SENSEI_NRF9151_LINK_H_

#include "sensei_lpwan/link_slave.h"

/** Start the link thread. The slave answers requests from now on, also while the modem boots. */
int link_start(link_slave_request_fn on_request, void *user);

/** Respond to the request being handled (call from on_request). */
int link_respond(const sensei_LpwanResponse *rsp);

/** Queue an event for the master. Safe from any thread. */
int link_push_event(const sensei_LpwanEvent *evt);

/** Events dropped since start because the queue was full. */
uint32_t link_dropped_events(void);

/** Feed the watchdog of the link thread (a request that takes long, such as a flash erase, calls it). */
void link_feed_watchdog(void);

/** Level of the ACK line (the master holds it high while the link is open). */
bool link_master_present(void);

#endif /* SENSEI_NRF9151_LINK_H_ */
```

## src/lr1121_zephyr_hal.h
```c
/*
 * SPDX-FileCopyrightText: 2026 ETH Zurich and University of Bologna
 * SPDX-License-Identifier: Apache-2.0
 *
 * Authors:
 * - Philip Wiese <wiesep@iis.ee.ethz.ch>
 */

/**
 * @file lr1121_zephyr_hal.h
 * @brief The LR1121 context (devicetree specs) for the Modem-E driver.
 */

#ifndef SENSEI_LR1121_ZEPHYR_HAL_H_
#define SENSEI_LR1121_ZEPHYR_HAL_H_

#include "lr1121_modem_hal.h"

/** The one LR1121 on the shield. Pass it as `context` to the driver calls. */
extern struct lr1121_context lr1121_ctx;

/** Check the devicetree devices and park the pins (radio held in reset). */
int lr1121_hal_init(void);

#endif /* SENSEI_LR1121_ZEPHYR_HAL_H_ */
```
